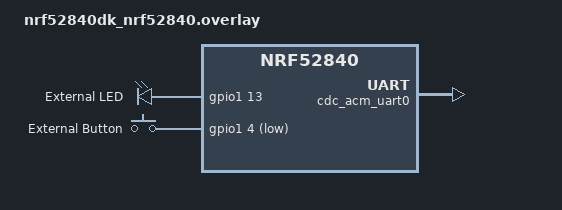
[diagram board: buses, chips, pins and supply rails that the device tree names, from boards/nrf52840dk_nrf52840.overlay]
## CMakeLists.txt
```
cmake_minimum_required(VERSION 3.20.0)

find_package(Zephyr REQUIRED HINTS $ENV{ZEPHYR_BASE})
project(fth_bt_gatt)

target_sources(app PRIVATE
    src/main.c
    src/gpio_app.c
    src/ble_service.c
)
```

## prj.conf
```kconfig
CONFIG_GPIO=y

CONFIG_SERIAL=y
CONFIG_CONSOLE=y
CONFIG_UART_CONSOLE=y

CONFIG_USB_DEVICE_STACK=y
CONFIG_USB_CDC_ACM=y
CONFIG_USB_DEVICE_INITIALIZE_AT_BOOT=y

CONFIG_CLOCK_CONTROL_NRF_K32SRC_RC=y
CONFIG_CLOCK_CONTROL_NRF_K32SRC_XTAL=n

CONFIG_BT=y
CONFIG_BT_PERIPHERAL=y
CONFIG_BT_DEVICE_NAME="E73_TEST"

CONFIG_BT_GATT_CLIENT=n
CONFIG_BT_ATT_PREPARE_COUNT=2
```

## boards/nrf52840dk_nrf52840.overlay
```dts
/ {
    chosen {
        zephyr,console = &cdc_acm_uart0;
    };

    leds {
        compatible = "gpio-leds";

        led0: led_0 {
            gpios = <&gpio1 13 GPIO_ACTIVE_HIGH>;
            label = "External LED";
        };
    };

    buttons {
        compatible = "gpio-keys";

        button0: button_0 {
            //gpios = <&gpio1 9 (GPIO_PULL_UP | GPIO_ACTIVE_LOW)>;
            gpios = <&gpio1 4 (GPIO_PULL_UP | GPIO_ACTIVE_LOW)>;
            label = "External Button";
        };
    };

    aliases {
        led0 = &led0;
        sw0 = &button0;
    };
};

&zephyr_udc0 {
    cdc_acm_uart0: cdc_acm_uart0 {
        compatible = "zephyr,cdc-acm-uart";
    };
};
```

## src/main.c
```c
#include <zephyr/kernel.h>
#include <zephyr/sys/printk.h>

#include "gpio_app.h"
#include "ble_service.h"

int main(void)
{
    int ret;

    printk("APP START\r\n");

    ret = gpio_app_init();
    if (ret < 0) {

        printk("GPIO init failed\r\n");

        return 0;
    }

    ret = ble_service_init();
    if (ret < 0) {

        printk("BLE init failed\r\n");

        return 0;
    }

    int last_button_state = 0;

    while (1)
    {
        int button_state = gpio_app_button_get();

        if (button_state != last_button_state)
        {
            last_button_state = button_state;

            if (button_state)
            {
                gpio_app_led_on();

                printk("BUTTON PRESSED\r\n");

                ble_service_notify("LED_ON");
            }
            else
            {
                gpio_app_led_off();

                printk("BUTTON RELEASED\r\n");

                ble_service_notify("LED_OFF");
            }
        }

        k_sleep(K_MSEC(50));
    }
}
```

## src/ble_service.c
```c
#include "ble_service.h"
#include "gpio_app.h"

#include <zephyr/kernel.h>
#include <zephyr/bluetooth/bluetooth.h>
#include <zephyr/bluetooth/conn.h>
#include <zephyr/bluetooth/gatt.h>
#include <zephyr/sys/printk.h>

#include <string.h>

static bool notify_enabled = false;
static char notify_value[32] = "SYSTEM_READY";

#define BT_UUID_FTH_SERVICE_VAL \
    BT_UUID_128_ENCODE(0x12345678, 0x1234, 0x5678, 0x1234, 0x56789abcdef0)

#define BT_UUID_FTH_LED_VAL \
    BT_UUID_128_ENCODE(0x12345679, 0x1234, 0x5678, 0x1234, 0x56789abcdef0)

static struct bt_uuid_128 fth_service_uuid =
    BT_UUID_INIT_128(BT_UUID_FTH_SERVICE_VAL);

static struct bt_uuid_128 fth_led_uuid =
    BT_UUID_INIT_128(BT_UUID_FTH_LED_VAL);

static const struct bt_data ad[] = {
    BT_DATA_BYTES(BT_DATA_FLAGS,
                  BT_LE_AD_GENERAL | BT_LE_AD_NO_BREDR),

    BT_DATA(BT_DATA_NAME_COMPLETE,
            CONFIG_BT_DEVICE_NAME,
            sizeof(CONFIG_BT_DEVICE_NAME) - 1),
};

static const struct bt_le_adv_param adv_param = {
    .id = BT_ID_DEFAULT,
    .sid = 0,
    .secondary_max_skip = 0,
    .options = BT_LE_ADV_OPT_CONN,
    .interval_min = BT_GAP_ADV_FAST_INT_MIN_2,
    .interval_max = BT_GAP_ADV_FAST_INT_MAX_2,
    .peer = NULL,
};

static void send_notify(void);

static ssize_t read_value(struct bt_conn *conn,
                          const struct bt_gatt_attr *attr,
                          void *buf,
                          uint16_t len,
                          uint16_t offset)
{
    return bt_gatt_attr_read(conn,
                             attr,
                             buf,
                             len,
                             offset,
                             notify_value,
                             strlen(notify_value));
}

static void ccc_cfg_changed(const struct bt_gatt_attr *attr,
                            uint16_t value)
{
    notify_enabled = (value == BT_GATT_CCC_NOTIFY);

    printk("Notify %s\r\n",
           notify_enabled ? "enabled" : "disabled");
}

static ssize_t write_led(struct bt_conn *conn,
                         const struct bt_gatt_attr *attr,
                         const void *buf,
                         uint16_t len,
                         uint16_t offset,
                         uint8_t flags)
{
    const uint8_t *data = buf;

    if (len < 1) {
        return BT_GATT_ERR(BT_ATT_ERR_INVALID_ATTRIBUTE_LEN);
    }

    if (data[0] == '1') {

        gpio_app_led_on();

        strcpy(notify_value, "LED_ON");

        printk("BLE WRITE: 1 -> LED ON\r\n");

        send_notify();

    } else if (data[0] == '0') {

        gpio_app_led_off();

        strcpy(notify_value, "LED_OFF");

        printk("BLE WRITE: 0 -> LED OFF\r\n");

        send_notify();
    }

    return len;
}

BT_GATT_SERVICE_DEFINE(fth_svc,

    BT_GATT_PRIMARY_SERVICE(&fth_service_uuid),

    BT_GATT_CHARACTERISTIC(&fth_led_uuid.uuid,
                           BT_GATT_CHRC_READ |
                           BT_GATT_CHRC_WRITE |
                           BT_GATT_CHRC_NOTIFY,

                           BT_GATT_PERM_READ |
                           BT_GATT_PERM_WRITE,

                           read_value,
                           write_led,
                           notify_value),

    BT_GATT_CCC(ccc_cfg_changed,
                BT_GATT_PERM_READ |
                BT_GATT_PERM_WRITE)
);

static void send_notify(void)
{
    if (!notify_enabled) {
        return;
    }

    bt_gatt_notify(NULL,
                   &fth_svc.attrs[2],
                   notify_value,
                   strlen(notify_value));
}

static void connected(struct bt_conn *conn, uint8_t err)
{
    if (err) {
        printk("Connection failed: %u\r\n", err);
        return;
    }

    gpio_app_led_on();

    printk("Connected\r\n");
}

static void disconnected(struct bt_conn *conn, uint8_t reason)
{
    gpio_app_led_off();

    printk("Disconnected: %u\r\n", reason);

    bt_le_adv_start(&adv_param,
                    ad,
                    ARRAY_SIZE(ad),
                    NULL,
                    0);
}

BT_CONN_CB_DEFINE(conn_callbacks) = {
    .connected = connected,
    .disconnected = disconnected,
};

int ble_service_init(void)
{
    int ret;

    ret = bt_enable(NULL);
    if (ret) {

        printk("Bluetooth init failed: %d\r\n", ret);

        return ret;
    }

    printk("Bluetooth initialized\r\n");

    ret = bt_le_adv_start(&adv_param,
                          ad,
                          ARRAY_SIZE(ad),
                          NULL,
                          0);

    if (ret) {

        printk("Advertising failed: %d\r\n", ret);

        return ret;
    }

    printk("Advertising started\r\n");

    return 0;
}

void ble_service_notify(const char *msg)
{
    strcpy(notify_value, msg);

    send_notify();
}
```

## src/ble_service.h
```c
#ifndef BLE_SERVICE_H
#define BLE_SERVICE_H

int ble_service_init(void);

void ble_service_notify(const char *msg);

#endif
```

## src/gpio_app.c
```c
#include "gpio_app.h"
#include <zephyr/sys/printk.h>

static const struct gpio_dt_spec led =
    GPIO_DT_SPEC_GET(DT_ALIAS(led0), gpios);

static const struct gpio_dt_spec button =
    GPIO_DT_SPEC_GET(DT_ALIAS(sw0), gpios);

int gpio_app_init(void)
{
    int ret;

    if (!device_is_ready(led.port)) {
        printk("LED device not ready\r\n");
        return -1;
    }

    if (!device_is_ready(button.port)) {
        printk("Button device not ready\r\n");
        return -1;
    }

    ret = gpio_pin_configure_dt(&led, GPIO_OUTPUT_INACTIVE);
    if (ret < 0) {
        printk("LED config failed: %d\r\n", ret);
        return ret;
    }

    ret = gpio_pin_configure_dt(&button, GPIO_INPUT);
    if (ret < 0) {
        printk("Button config failed: %d\r\n", ret);
        return ret;
    }

    return 0;
}

void gpio_app_led_on(void)
{
    gpio_pin_set_dt(&led, 1);
}

void gpio_app_led_off(void)
{
    gpio_pin_set_dt(&led, 0);
}

int gpio_app_button_get(void)
{
    return gpio_pin_get_dt(&button);
}
```

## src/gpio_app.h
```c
#ifndef GPIO_APP_H
#define GPIO_APP_H

#include <zephyr/drivers/gpio.h>

int gpio_app_init(void);

void gpio_app_led_on(void);
void gpio_app_led_off(void);

int gpio_app_button_get(void);

#endif
```
